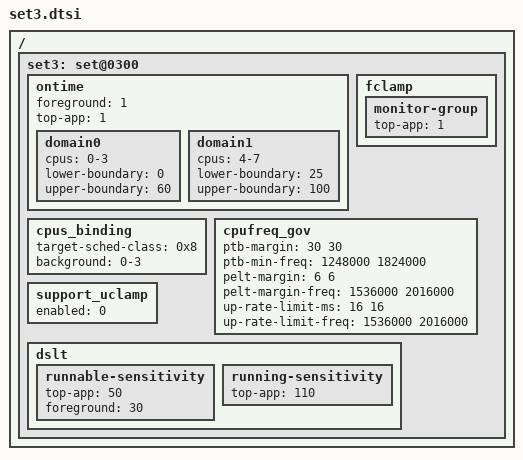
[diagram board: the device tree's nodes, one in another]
/ {
	/* game mode - default */
	set3: set@0300{
		/* Ontime Migration */
		ontime {
			foreground	= <1>;
			top-app		= <1>;

			domain0 {
				cpus = "0-3";
				lower-boundary = <0>;
				upper-boundary = <60>;
			};
			domain1 {
				cpus = "4-7";
				lower-boundary = <25>;
				upper-boundary = <100>;
			};
		};

		/* cpus_binding applied to core selection */
		cpus_binding {
			target-sched-class = <0x8>;	/* fair */
			background	= "0-3";
		};

		fclamp {
			monitor-group {
				top-app = <1>;
			};
		};

		cpufreq_gov {
			/* LIT BIG */
			ptb-margin = <30 30>;
			ptb-min-freq = <1248000 1824000>;

			/* LIT BIG */
			pelt-margin = <6 6>;
			pelt-margin-freq = <1536000 2016000>;
			up-rate-limit-ms = <16 16>;
			up-rate-limit-freq = <1536000 2016000>;
		};

		support_uclamp {
			enabled = <0>;
		};

		dslt {
			runnable-sensitivity {
				top-app    = <50>;
				foreground = <30>;
			};
			running-sensitivity {
				top-app    = <110>;
			};
		};
	};
};
